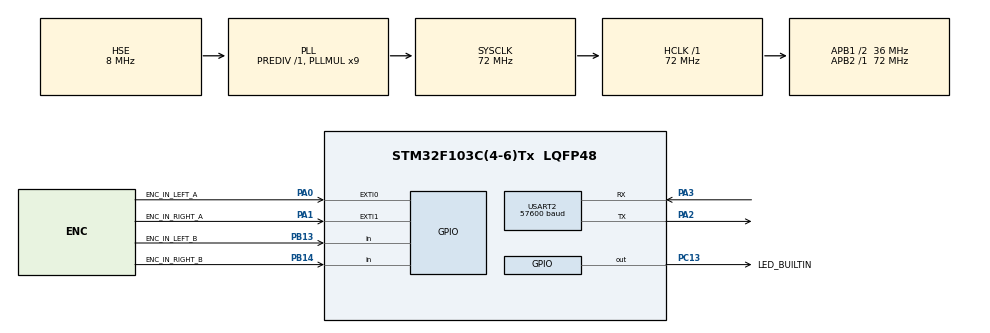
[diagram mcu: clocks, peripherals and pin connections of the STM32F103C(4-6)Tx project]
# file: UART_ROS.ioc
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Dma.Request0=USART2_RX
Dma.Request1=USART2_TX
Dma.USART2_RX.0.Direction=DMA_PERIPH_TO_MEMORY
Dma.USART2_RX.0.Instance=DMA1_Channel6
Dma.USART2_RX.0.MemDataAlignment=DMA_MDATAALIGN_BYTE
Dma.USART2_RX.0.MemInc=DMA_MINC_ENABLE
Dma.USART2_RX.0.Mode=DMA_CIRCULAR
Dma.USART2_RX.0.PeriphDataAlignment=DMA_PDATAALIGN_BYTE
Dma.USART2_RX.0.PeriphInc=DMA_PINC_DISABLE
Dma.USART2_RX.0.Priority=DMA_PRIORITY_HIGH
Dma.USART2_TX.1.Direction=DMA_MEMORY_TO_PERIPH
Dma.USART2_TX.1.Instance=DMA1_Channel7
Dma.USART2_TX.1.MemDataAlignment=DMA_MDATAALIGN_BYTE
Dma.USART2_TX.1.MemInc=DMA_MINC_ENABLE
Dma.USART2_TX.1.Mode=DMA_NORMAL
Dma.USART2_TX.1.PeriphDataAlignment=DMA_PDATAALIGN_BYTE
Dma.USART2_TX.1.PeriphInc=DMA_PINC_DISABLE
Dma.USART2_TX.1.Priority=DMA_PRIORITY_HIGH
Mcu.Family=STM32F1
Mcu.Name=STM32F103C(4-6)Tx
Mcu.Package=LQFP48
NVIC.DMA1_Channel6_IRQn=true\:0\:0\:false\:false\:true\:false\:true\:true
NVIC.DMA1_Channel7_IRQn=true\:0\:0\:false\:false\:true\:false\:true\:true
NVIC.EXTI0_IRQn=true\:0\:0\:false\:false\:true\:true\:true\:true
NVIC.EXTI1_IRQn=true\:0\:0\:false\:false\:true\:true\:true\:true
NVIC.PriorityGroup=NVIC_PRIORITYGROUP_4
NVIC.USART2_IRQn=true\:0\:0\:false\:false\:true\:true\:true\:true
PA0-WKUP.GPIO_Label=ENC_IN_LEFT_A
PA0-WKUP.GPIO_ModeDefaultEXTI=GPIO_MODE_IT_RISING
PA0-WKUP.Signal=GPXTI0
PA1.GPIO_Label=ENC_IN_RIGHT_A
PA1.Signal=GPXTI1
PA2.Mode=Asynchronous
PA2.Signal=USART2_TX
PA3.Mode=Asynchronous
PA3.Signal=USART2_RX
PB13.GPIO_Label=ENC_IN_LEFT_B
PB13.Signal=GPIO_Input
PB14.GPIO_Label=ENC_IN_RIGHT_B
PB14.Signal=GPIO_Input
PC13-TAMPER-RTC.GPIO_Label=LED_BUILTIN
PC13-TAMPER-RTC.Signal=GPIO_Output
PD0-OSC_IN.Mode=HSE-External-Oscillator
PD0-OSC_IN.Signal=RCC_OSC_IN
PD1-OSC_OUT.Mode=HSE-External-Oscillator
PD1-OSC_OUT.Signal=RCC_OSC_OUT
ProjectManager.HeapSize=0x200
ProjectManager.StackSize=0x400
ProjectManager.TargetToolchain=STM32CubeIDE
RCC.AHBFreq_Value=72000000
RCC.APB1CLKDivider=RCC_HCLK_DIV2
RCC.APB1Freq_Value=36000000
RCC.APB1TimFreq_Value=72000000
RCC.APB2Freq_Value=72000000
RCC.APB2TimFreq_Value=72000000
RCC.HCLKFreq_Value=72000000
RCC.PLLMUL=RCC_PLL_MUL9
RCC.PLLSourceVirtual=RCC_PLLSOURCE_HSE
RCC.SYSCLKFreq_VALUE=72000000
RCC.SYSCLKSource=RCC_SYSCLKSOURCE_PLLCLK
RCC.USBFreq_Value=72000000
USART2.BaudRate=57600
USART2.VirtualMode=VM_ASYNC
VP_SYS_VS_ND.Mode=No_Debug
board=custom

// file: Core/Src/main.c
/* USER CODE BEGIN Header */
/**
  ******************************************************************************
  * @file           : main.c
  * @brief          : Main program body
  ******************************************************************************
  * @attention
  *
  * Copyright (c) 2024 STMicroelectronics.
  * All rights reserved.
  *
  * This software is licensed under terms that can be found in the LICENSE file
  * in the root directory of this software component.
  * If no LICENSE file comes with this software, it is provided AS-IS.
  *
  ******************************************************************************
  */
/* USER CODE END Header */
#include "main.h"

/* USER CODE BEGIN Includes */
#include <mainpp.h>
/* USER CODE END Includes */

UART_HandleTypeDef huart2;
DMA_HandleTypeDef hdma_usart2_rx;
DMA_HandleTypeDef hdma_usart2_tx;

void SystemClock_Config(void);
static void MX_GPIO_Init(void);
static void MX_DMA_Init(void);
static void MX_USART2_UART_Init(void);

int main(void)
{

  /* MCU Configuration--------------------------------------------------------*/

  /* Reset of all peripherals, Initializes the Flash interface and the Systick. */
  HAL_Init();

  /* Configure the system clock */
  SystemClock_Config();

  /* Initialize all configured peripherals */
  MX_GPIO_Init();
  MX_DMA_Init();
  MX_USART2_UART_Init();
  /* USER CODE BEGIN 2 */
  setup();
  /* USER CODE END 2 */

  /* Infinite loop */
  /* USER CODE BEGIN WHILE */
  while (1)
  {
	  loop();
    /* USER CODE END WHILE */

  }
}

void SystemClock_Config(void)
{
  RCC_OscInitTypeDef RCC_OscInitStruct = {0};
  RCC_ClkInitTypeDef RCC_ClkInitStruct = {0};

  /** Initializes the RCC Oscillators according to the specified parameters
  * in the RCC_OscInitTypeDef structure.
  */
  RCC_OscInitStruct.OscillatorType = RCC_OSCILLATORTYPE_HSE;
  RCC_OscInitStruct.HSEState = RCC_HSE_ON;
  RCC_OscInitStruct.HSEPredivValue = RCC_HSE_PREDIV_DIV1;
  RCC_OscInitStruct.HSIState = RCC_HSI_ON;
  RCC_OscInitStruct.PLL.PLLState = RCC_PLL_ON;
  RCC_OscInitStruct.PLL.PLLSource = RCC_PLLSOURCE_HSE;
  RCC_OscInitStruct.PLL.PLLMUL = RCC_PLL_MUL9;
  if (HAL_RCC_OscConfig(&RCC_OscInitStruct) != HAL_OK)
  {
    Error_Handler();
  }

  /** Initializes the CPU, AHB and APB buses clocks
  */
  RCC_ClkInitStruct.ClockType = RCC_CLOCKTYPE_HCLK|RCC_CLOCKTYPE_SYSCLK
                              |RCC_CLOCKTYPE_PCLK1|RCC_CLOCKTYPE_PCLK2;
  RCC_ClkInitStruct.SYSCLKSource = RCC_SYSCLKSOURCE_PLLCLK;
  RCC_ClkInitStruct.AHBCLKDivider = RCC_SYSCLK_DIV1;
  RCC_ClkInitStruct.APB1CLKDivider = RCC_HCLK_DIV2;
  RCC_ClkInitStruct.APB2CLKDivider = RCC_HCLK_DIV1;

  if (HAL_RCC_ClockConfig(&RCC_ClkInitStruct, FLASH_LATENCY_2) != HAL_OK)
  {
    Error_Handler();
  }
}

static void MX_USART2_UART_Init(void)
{

  huart2.Instance = USART2;
  huart2.Init.BaudRate = 57600;
  huart2.Init.WordLength = UART_WORDLENGTH_8B;
  huart2.Init.StopBits = UART_STOPBITS_1;
  huart2.Init.Parity = UART_PARITY_NONE;
  huart2.Init.Mode = UART_MODE_TX_RX;
  huart2.Init.HwFlowCtl = UART_HWCONTROL_NONE;
  huart2.Init.OverSampling = UART_OVERSAMPLING_16;
  if (HAL_UART_Init(&huart2) != HAL_OK)
  {
    Error_Handler();
  }

}

static void MX_DMA_Init(void)
{

  /* DMA controller clock enable */
  __HAL_RCC_DMA1_CLK_ENABLE();

  /* DMA interrupt init */
  /* DMA1_Channel6_IRQn interrupt configuration */
  HAL_NVIC_SetPriority(DMA1_Channel6_IRQn, 0, 0);
  HAL_NVIC_EnableIRQ(DMA1_Channel6_IRQn);
  /* DMA1_Channel7_IRQn interrupt configuration */
  HAL_NVIC_SetPriority(DMA1_Channel7_IRQn, 0, 0);
  HAL_NVIC_EnableIRQ(DMA1_Channel7_IRQn);

}

static void MX_GPIO_Init(void)
{
  GPIO_InitTypeDef GPIO_InitStruct = {0};

  /* GPIO Ports Clock Enable */
  __HAL_RCC_GPIOC_CLK_ENABLE();
  __HAL_RCC_GPIOD_CLK_ENABLE();
  __HAL_RCC_GPIOA_CLK_ENABLE();
  __HAL_RCC_GPIOB_CLK_ENABLE();

  /*Configure GPIO pin Output Level */
  HAL_GPIO_WritePin(LED_BUILTIN_GPIO_Port, LED_BUILTIN_Pin, GPIO_PIN_RESET);

  /*Configure GPIO pin : LED_BUILTIN_Pin */
  GPIO_InitStruct.Pin = LED_BUILTIN_Pin;
  GPIO_InitStruct.Mode = GPIO_MODE_OUTPUT_PP;
  GPIO_InitStruct.Pull = GPIO_NOPULL;
  GPIO_InitStruct.Speed = GPIO_SPEED_FREQ_LOW;
  HAL_GPIO_Init(LED_BUILTIN_GPIO_Port, &GPIO_InitStruct);

  /*Configure GPIO pins : ENC_IN_LEFT_A_Pin ENC_IN_RIGHT_A_Pin */
  GPIO_InitStruct.Pin = ENC_IN_LEFT_A_Pin|ENC_IN_RIGHT_A_Pin;
  GPIO_InitStruct.Mode = GPIO_MODE_IT_RISING;
  GPIO_InitStruct.Pull = GPIO_NOPULL;
  HAL_GPIO_Init(GPIOA, &GPIO_InitStruct);

  /*Configure GPIO pins : ENC_IN_LEFT_B_Pin ENC_IN_RIGHT_B_Pin */
  GPIO_InitStruct.Pin = ENC_IN_LEFT_B_Pin|ENC_IN_RIGHT_B_Pin;
  GPIO_InitStruct.Mode = GPIO_MODE_INPUT;
  GPIO_InitStruct.Pull = GPIO_NOPULL;
  HAL_GPIO_Init(GPIOB, &GPIO_InitStruct);

  /* EXTI interrupt init*/
  HAL_NVIC_SetPriority(EXTI0_IRQn, 0, 0);
  HAL_NVIC_EnableIRQ(EXTI0_IRQn);

  HAL_NVIC_SetPriority(EXTI1_IRQn, 0, 0);
  HAL_NVIC_EnableIRQ(EXTI1_IRQn);

}

/* USER CODE BEGIN 4 */

void HAL_GPIO_EXTI_Callback(uint16_t GPIO_Pin)
{
    switch(GPIO_Pin){
    case ENC_IN_LEFT_A_Pin:
    	left_wheel_tick();
    	break;
    case ENC_IN_RIGHT_A_Pin:
    	right_wheel_tick();
    	break;
    }
}

/* USER CODE END 4 */

void Error_Handler(void)
{
  __disable_irq();
  while (1)
  {
  }
}
